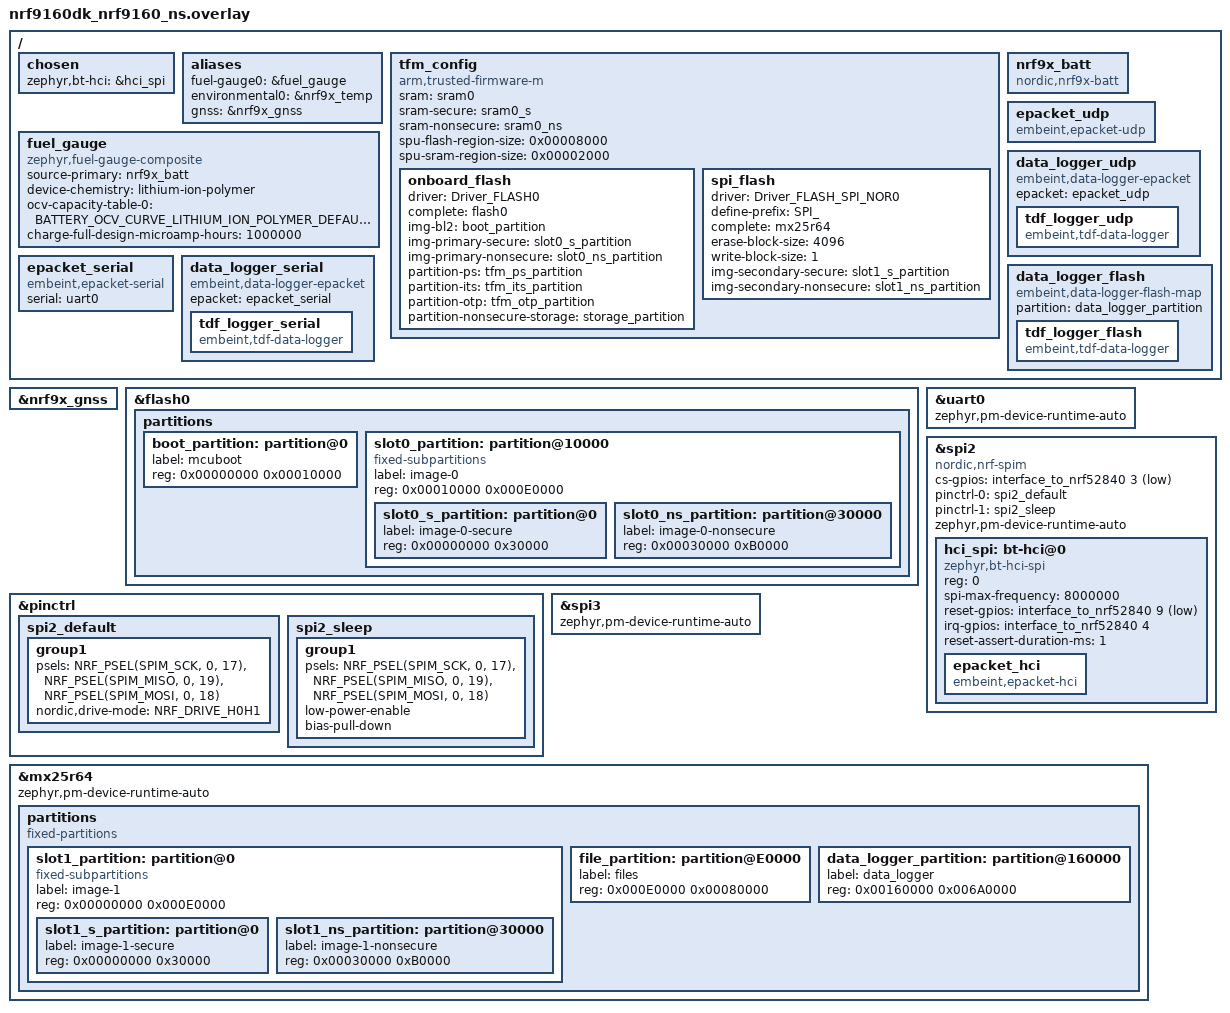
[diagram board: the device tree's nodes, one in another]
/*
 * Copyright (c) 2025 Embeint Holdings Pty Ltd
 * SPDX-License-Identifier: FSL-1.1-ALv2
 */

#include <zephyr/dt-bindings/battery/battery.h>
#include <common/nordic/infuse_nrf9160_ns.dtsi>
#include <common/infuse_bluetooth.dtsi>

/* MCUboot secondary on external flash */
/delete-node/ &slot0_partition;
/delete-node/ &slot1_partition;

/ {
	chosen {
		zephyr,bt-hci = &hci_spi;
	};

	aliases {
		fuel-gauge0 = &fuel_gauge;
		environmental0 = &nrf9x_temp;
		gnss = &nrf9x_gnss;
	};

	tfm_config {
		compatible = "arm,trusted-firmware-m";
		sram = <&sram0>;
		sram-secure = <&sram0_s>;
		sram-nonsecure = <&sram0_ns>;
		spu-flash-region-size = <0x00008000>;
		spu-sram-region-size = <0x00002000>;

		onboard_flash {
			driver = "Driver_FLASH0";
			complete = <&flash0>;
			img-bl2 = <&boot_partition>;
			img-primary-secure = <&slot0_s_partition>;
			img-primary-nonsecure = <&slot0_ns_partition>;
			partition-ps = <&tfm_ps_partition>;
			partition-its = <&tfm_its_partition>;
			partition-otp = <&tfm_otp_partition>;
			partition-nonsecure-storage = <&storage_partition>;
		};

		spi_flash {
			driver = "Driver_FLASH_SPI_NOR0";
			define-prefix = "SPI_";
			complete = <&mx25r64>;
			erase-block-size = <4096>;
			write-block-size = <1>;
			img-secondary-secure = <&slot1_s_partition>;
			img-secondary-nonsecure = <&slot1_ns_partition>;
		};
	};

	nrf9x_batt: nrf9x_batt {
		compatible = "nordic,nrf9x-batt";
	};

	fuel_gauge: fuel_gauge {
		compatible = "zephyr,fuel-gauge-composite";
		source-primary = <&nrf9x_batt>;
		device-chemistry = "lithium-ion-polymer";
		ocv-capacity-table-0 = <BATTERY_OCV_CURVE_LITHIUM_ION_POLYMER_DEFAULT>;
		charge-full-design-microamp-hours = <1000000>;
	};

	epacket_udp: epacket_udp {
		compatible = "embeint,epacket-udp";
	};

	data_logger_udp: data_logger_udp {
		compatible = "embeint,data-logger-epacket", "embeint,data-logger";
		epacket = <&epacket_udp>;

		tdf_logger_udp: tdf_logger_udp {
			compatible = "embeint,tdf-data-logger";
		};
	};

	epacket_serial: epacket_serial {
		compatible = "embeint,epacket-serial";
		serial = <&uart0>;
	};

	data_logger_serial: data_logger_serial {
		compatible = "embeint,data-logger-epacket", "embeint,data-logger";
		epacket = <&epacket_serial>;

		tdf_logger_serial: tdf_logger_serial {
			compatible = "embeint,tdf-data-logger";
		};
	};

	data_logger_flash: data_logger_flash {
		compatible = "embeint,data-logger-flash-map", "embeint,data-logger";
		partition = <&data_logger_partition>;

		tdf_logger_flash: tdf_logger_flash {
			compatible = "embeint,tdf-data-logger";
		};
	};
};

&nrf9x_gnss {
	status = "okay";
};

&flash0 {
	partitions {
		boot_partition: partition@0 {
			label = "mcuboot";
			reg = <0x00000000 0x00010000>;
		};
		slot0_partition: partition@10000 {
			compatible = "fixed-subpartitions";
			label = "image-0";
			reg = <0x00010000 0x000E0000>;
			ranges = <0x0 0x10000 0xE0000>;
			#address-cells = <1>;
			#size-cells = <1>;

			slot0_s_partition: partition@0 {
				label = "image-0-secure";
				reg = <0x00000000 0x30000>;
			};

			slot0_ns_partition: partition@30000 {
				label = "image-0-nonsecure";
				reg = <0x00030000 0xB0000>;
			};
		};
	};
};

&uart0 {
	zephyr,pm-device-runtime-auto;
};

&pinctrl {
	spi2_default: spi2_default {
		group1 {
			psels = <NRF_PSEL(SPIM_SCK, 0, 17)>,
				<NRF_PSEL(SPIM_MISO, 0, 19)>,
				<NRF_PSEL(SPIM_MOSI, 0, 18)>;
			nordic,drive-mode = <NRF_DRIVE_H0H1>;
		};
	};

	spi2_sleep: spi2_sleep {
		group1 {
			psels = <NRF_PSEL(SPIM_SCK, 0, 17)>,
				<NRF_PSEL(SPIM_MISO, 0, 19)>,
				<NRF_PSEL(SPIM_MOSI, 0, 18)>;
			low-power-enable;
			bias-pull-down;
		};
	};
};

&spi2 {
	compatible = "nordic,nrf-spim";
	status = "okay";
	cs-gpios = <&interface_to_nrf52840 3 GPIO_ACTIVE_LOW>;
	pinctrl-0 = <&spi2_default>;
	pinctrl-1 = <&spi2_sleep>;
	pinctrl-names = "default", "sleep";
	zephyr,pm-device-runtime-auto;

	/* Nordic nRF52840 */
	hci_spi: bt-hci@0 {
		compatible = "zephyr,bt-hci-spi";
		reg = <0>;
		spi-max-frequency = <8000000>;
		reset-gpios = <&interface_to_nrf52840 9 GPIO_ACTIVE_LOW>;
		irq-gpios = <&interface_to_nrf52840 4 GPIO_ACTIVE_HIGH>;
		reset-assert-duration-ms = <1>;
		epacket_hci: epacket_hci {
			compatible = "embeint,epacket-hci";
		};
	};
};

&spi3 {
	zephyr,pm-device-runtime-auto;
};

&mx25r64 {
	zephyr,pm-device-runtime-auto;

	partitions {
		compatible = "fixed-partitions";
		#address-cells = <1>;
		#size-cells = <1>;

		slot1_partition: partition@0 {
			compatible = "fixed-subpartitions";
			label = "image-1";
			reg = <0x00000000 0x000E0000>;
			ranges = <0x0 0x0 0xE0000>;
			#address-cells = <1>;
			#size-cells = <1>;

			slot1_s_partition: partition@0 {
				label = "image-1-secure";
				reg = <0x00000000 0x30000>;
			};

			slot1_ns_partition: partition@30000 {
				label = "image-1-nonsecure";
				reg = <0x00030000 0xB0000>;
			};

		};
		file_partition: partition@E0000 {
			label = "files";
			reg = <0x000E0000 0x00080000>;
		};
		data_logger_partition: partition@160000 {
			label = "data_logger";
			reg = <0x00160000 0x006A0000>;
		};
	};
};
